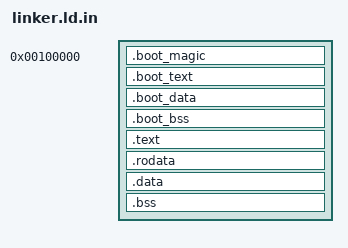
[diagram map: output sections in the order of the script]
OUTPUT_FORMAT("elf32-i386")
OUTPUT_ARCH("i386")
ENTRY(_start)

#define KERNEL_OFFSET 0xC0000000

SECTIONS
{
    . = 0x00100000;
    kernel_base_addr = .;

    boot_base_addr = .;

    .boot_magic : {
        *(.boot_magic)
    }

    .boot_text : ALIGN(4K) {
        *(.boot_text)
    }

    .boot_data : ALIGN(4K) {
        *(.boot_data)
    }

    .boot_bss : ALIGN(4K) {
        *(.boot_bss)
    }

    boot_end_addr = .;

    . += KERNEL_OFFSET;

    .text ALIGN(4K) : AT(ADDR(.text) - KERNEL_OFFSET) {
        kernel_code_base = .;
        *(.text)
    }

    .rodata ALIGN(4K) : AT(ADDR(.rodata) - KERNEL_OFFSET) {
        *(.rodata)
        kernel_code_end = .;
    }

    .data ALIGN(4K) : AT(ADDR(.data) - KERNEL_OFFSET) {
        kernel_data_base = .;
        *(.data)
    }

    .bss ALIGN(4K) : AT(ADDR(.bss) - KERNEL_OFFSET) {
        *(COMMON)
        *(.bss)
        kernel_data_end = .;
    }

    kernel_end_addr = .;
}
